AUTOSAR XML (schema 00046)
package /ComponentTypes
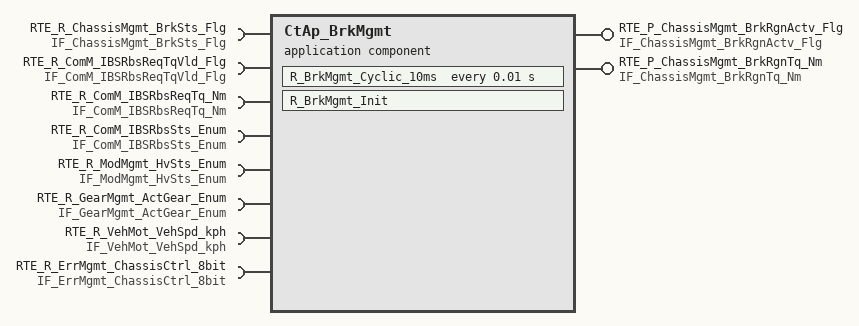
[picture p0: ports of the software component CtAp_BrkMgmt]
  application sw component type CtAp_BrkMgmt
    provide port RTE_P_ChassisMgmt_BrkRgnActv_Flg: nonqueued-sender-com-spec{data-element=tec_ChassisMgmt_BrkRgnActv_Flg, init-value=0}, provided-interface=IF_ChassisMgmt_BrkRgnActv_Flg
    provide port RTE_P_ChassisMgmt_BrkRgnTq_Nm: nonqueued-sender-com-spec{data-element=tec_ChassisMgmt_BrkRgnTq_Nm, init-value=0}, provided-interface=IF_ChassisMgmt_BrkRgnTq_Nm
    8 x require port:
      RTE_R_ChassisMgmt_BrkSts_Flg: nonqueued-receiver-com-spec{data-element=tec_ChassisMgmt_BrkSts_Flg, filter=data-filter-type=ALWAYS, init-value=0}, required-interface=IF_ChassisMgmt_BrkSts_Flg
      RTE_R_ComM_IBSRbsReqTqVld_Flg: nonqueued-receiver-com-spec{data-element=tec_ComM_IBSRbsReqTqVld_Flg, filter=data-filter-type=ALWAYS, init-value=0}, required-interface=IF_ComM_IBSRbsReqTqVld_Flg
      RTE_R_ComM_IBSRbsReqTq_Nm: nonqueued-receiver-com-spec{data-element=tec_ComM_IBSRbsReqTq_Nm, filter=data-filter-type=ALWAYS, init-value=0}, required-interface=IF_ComM_IBSRbsReqTq_Nm
      RTE_R_ComM_IBSRbsSts_Enum: nonqueued-receiver-com-spec{data-element=tec_ComM_IBSRbsSts_Enum, filter=data-filter-type=ALWAYS, init-value=0}, required-interface=IF_ComM_IBSRbsSts_Enum
      RTE_R_ModMgmt_HvSts_Enum: nonqueued-receiver-com-spec{data-element=tec_ModMgmt_HvSts_Enum, filter=data-filter-type=ALWAYS, init-value=0}, required-interface=IF_ModMgmt_HvSts_Enum
      RTE_R_GearMgmt_ActGear_Enum: nonqueued-receiver-com-spec{data-element=tec_GearMgmt_ActGear_Enum, filter=data-filter-type=ALWAYS, init-value=0}, required-interface=IF_GearMgmt_ActGear_Enum
      RTE_R_VehMot_VehSpd_kph: nonqueued-receiver-com-spec{data-element=tec_VehMot_VehSpd_kph, filter=data-filter-type=ALWAYS, init-value=0}, required-interface=IF_VehMot_VehSpd_kph
      RTE_R_ErrMgmt_ChassisCtrl_8bit: nonqueued-receiver-com-spec{data-element=tec_ErrMgmt_ChassisCtrl_8bit, filter=data-filter-type=ALWAYS, init-value=0}, required-interface=IF_ErrMgmt_ChassisCtrl_8bit
    behavior CtAp_BrkMgmt_InternalBehavior
      init event CtAp_BrkMgmt_InitEvent: start-on-event=R_BrkMgmt_Init
      timing event TMT_R_BrkMgmt_Cyclic_10ms: start-on-event=R_BrkMgmt_Cyclic_10ms, period=0.01
      runnable R_BrkMgmt_Init
      runnable R_BrkMgmt_Cyclic_10ms
        data-receive-point-by-arguments:
          8 x access:
            REC_RTE_R_ChassisMgmt_BrkSts_Flg_tec_ChassisMgmt_BrkSts_Flg: accessed-variable=RTE_R_ChassisMgmt_BrkSts_Flg.tec_ChassisMgmt_BrkSts_Flg
            REC_RTE_R_ComM_IBSRbsReqTqVld_Flg_tec_ComM_IBSRbsReqTqVld_Flg: accessed-variable=RTE_R_ComM_IBSRbsReqTqVld_Flg.tec_ComM_IBSRbsReqTqVld_Flg
            REC_RTE_R_ComM_IBSRbsReqTq_Nm_tec_ComM_IBSRbsReqTq_Nm: accessed-variable=RTE_R_ComM_IBSRbsReqTq_Nm.tec_ComM_IBSRbsReqTq_Nm
            REC_RTE_R_ComM_IBSRbsSts_Enum_tec_ComM_IBSRbsSts_Enum: accessed-variable=RTE_R_ComM_IBSRbsSts_Enum.tec_ComM_IBSRbsSts_Enum
            REC_RTE_R_ErrMgmt_ChassisCtrl_8bit_tec_ErrMgmt_ChassisCtrl_8bit: accessed-variable=RTE_R_ErrMgmt_ChassisCtrl_8bit.tec_ErrMgmt_ChassisCtrl_8bit
            REC_RTE_R_GearMgmt_ActGear_Enum_tec_GearMgmt_ActGear_Enum: accessed-variable=RTE_R_GearMgmt_ActGear_Enum.tec_GearMgmt_ActGear_Enum
            REC_RTE_R_ModMgmt_HvSts_Enum_tec_ModMgmt_HvSts_Enum: accessed-variable=RTE_R_ModMgmt_HvSts_Enum.tec_ModMgmt_HvSts_Enum
            REC_RTE_R_VehMot_VehSpd_kph_tec_VehMot_VehSpd_kph: accessed-variable=RTE_R_VehMot_VehSpd_kph.tec_VehMot_VehSpd_kph
        data-send-points:
          access SEND_RTE_P_ChassisMgmt_BrkRgnActv_Flg_tec_ChassisMgmt_BrkRgnActv_Flg: accessed-variable=RTE_P_ChassisMgmt_BrkRgnActv_Flg.tec_ChassisMgmt_BrkRgnActv_Flg
          access SEND_RTE_P_ChassisMgmt_BrkRgnTq_Nm_tec_ChassisMgmt_BrkRgnTq_Nm: accessed-variable=RTE_P_ChassisMgmt_BrkRgnTq_Nm.tec_ChassisMgmt_BrkRgnTq_Nm
  swc implementation CtAp_BrkMgmt_Implementation: behavior=CtAp_BrkMgmt_InternalBehavior
    code-descriptors:
      code Default: artifact-descriptors=autosar-engineering-object=category=SWOBJ
